# R7FA8D1BH register map
Vendor: Renesas; Series: RA8; File version: 1.2
CPU: CM85 r0p0, little endian, MPU, FPU, VTOR, 4 interrupt priority bits
Registers are 32-bit, read-write, reset 0x0 unless marked. A register's access mark holds for its fields unless they carry their own. Offsets are from the block's base; [hi:lo] are bit positions; 'fields as' and 'values as' point back to an identical list.

## MSTP — Module Stop Control A,B,C,D,E
Base 0x40203000
Same registers: MSTP_NS 0x50203000
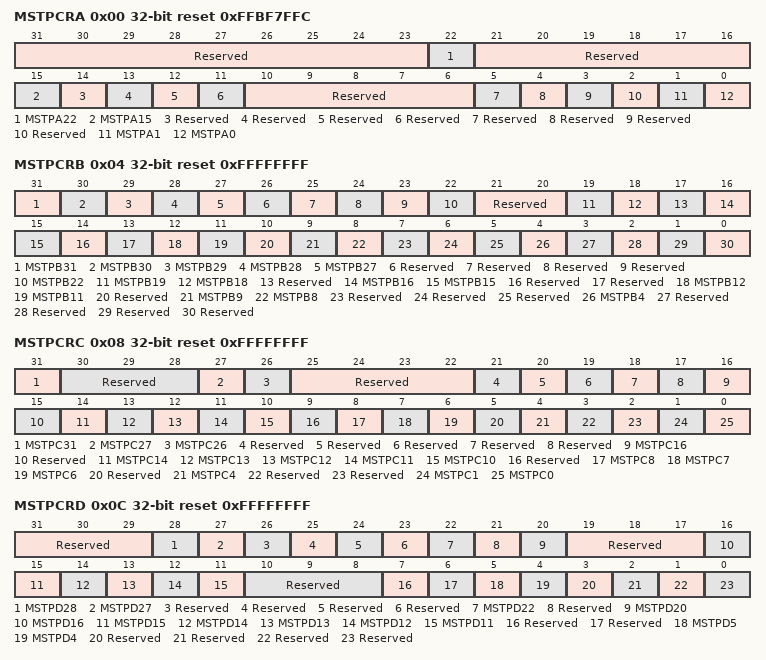
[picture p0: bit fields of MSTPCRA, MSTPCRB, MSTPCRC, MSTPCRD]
0x00 MSTPCRA reset 0xFFBF7FFC — Module Stop Control Register A
  [31:23] Reserved — These bits are read as 111111111. The write value should be 111111111.
  [22] MSTPA22 — DMA Controller/Data Transfer Controller unit0 Module Stop
    0=Cancel the module-stop state; 1=Enter the module-stop state
  [21:16] Reserved — These bits are read as 111111. The write value should be 111111.
  [15] MSTPA15 — Standby SRAM Module Module Stop
    values as MSTPA22
  [14] Reserved — This bit is read as 1. The write value should be 1.
  [13] Reserved — This bit is read as 1. The write value should be 1.
  [12] Reserved — This bit is read as 1. The write value should be 1.
  [11] Reserved — This bit is read as 1. The write value should be 1.
  [10:6] Reserved — These bits are read as 11111. The write value should be 11111.
  [5] Reserved — This bit is read as 1. The write value should be 1.
  [4] Reserved — This bit is read as 1. The write value should be 1.
  [3] Reserved — This bit is read as 1. The write value should be 1.
  [2] Reserved — This bit is read as 1. The write value should be 1.
  [1] MSTPA1 — SRAM1 Module Stop
    values as MSTPA22
  [0] MSTPA0 — SRAM0 Module Stop
    values as MSTPA22
0x04 MSTPCRB reset 0xFFFFFFFF — Module Stop Control Register B
  [31] MSTPB31 — Serial Communication Interface 0 Module Stop
    values as MSTPCRA.MSTPA22
  [30] MSTPB30 — Serial Communication Interface 1 Module Stop
    values as MSTPCRA.MSTPA22
  [29] MSTPB29 — Serial Communication Interface 2 Module Stop
    values as MSTPCRA.MSTPA22
  [28] MSTPB28 — Serial Communication Interface 3 Module Stop
    values as MSTPCRA.MSTPA22
  [27] MSTPB27 — Serial Communication Interface 4 Module Stop
    values as MSTPCRA.MSTPA22
  [26] Reserved — This bit is read as 1. The write value should be 1.
  [25] Reserved — This bit is read as 1. The write value should be 1.
  [24] Reserved — This bit is read as 1. The write value should be 1.
  [23] Reserved — This bit is read as 1. The write value should be 1.
  [22] MSTPB22 — Serial Communication Interface 9 Module Stop
    values as MSTPCRA.MSTPA22
  [21:20] Reserved — These bits are read as 11. The write value should be 11.
  [19] MSTPB19 — Serial Peripheral Interface 0 Module Stop
    values as MSTPCRA.MSTPA22
  [18] MSTPB18 — Serial Peripheral Interface 1 Module Stop
    values as MSTPCRA.MSTPA22
  [17] Reserved — This bit is read as 1. The write value should be 1.
  [16] MSTPB16 — Octa Memory Controller Module Stop
    values as MSTPCRA.MSTPA22
  [15] MSTPB15 — ETHERC0 and EDMAC0 Module Stop
    values as MSTPCRA.MSTPA22
  [14] Reserved — This bit is read as 1. The write value should be 1.
  [13] Reserved — This bit is read as 1. The write value should be 1.
  [12] MSTPB12 — Universal Serial Bus 2.0 HS Interface Module Stop
    values as MSTPCRA.MSTPA22
  [11] MSTPB11 — Universal Serial Bus 2.0 FS0 Interface Module Stop
    values as MSTPCRA.MSTPA22
  [10] Reserved — This bit is read as 1. The write value should be 1.
  [9] MSTPB9 — I2C Bus Interface 0 Module Stop
    values as MSTPCRA.MSTPA22
  [8] MSTPB8 — I2C Bus Interface 1 Module Stop
    values as MSTPCRA.MSTPA22
  [7] Reserved — This bit is read as 1. The write value should be 1.
  [6] Reserved — This bit is read as 1. The write value should be 1.
  [5] Reserved — This bit is read as 1. The write value should be 1.
  [4] MSTPB4 — I3C Bus Interface Module Stop
    values as MSTPCRA.MSTPA22
  [3] Reserved — This bit is read as 1. The write value should be 1.
  [2] Reserved — This bit is read as 1. The write value should be 1.
  [1] Reserved — This bit is read as 1. The write value should be 1.
  [0] Reserved — This bit is read as 1. The write value should be 1.
0x08 MSTPCRC reset 0xFFFFFFFF — Module Stop Control Register C
  [31] MSTPC31 — SHIP Module Stop
    values as MSTPCRA.MSTPA22
  [30:28] Reserved — These bits are read as 111. The write value should be 111.
  [27] MSTPC27 — Controller Area Network with Flexible Data-Rate 0 Module Stop
    values as MSTPCRA.MSTPA22
  [26] MSTPC26 — Controller Area Network with Flexible Data-Rate 1 Module Stop
    values as MSTPCRA.MSTPA22
  [25:22] Reserved — These bits are read as 1111. The write value should be 1111.
  [21] Reserved — This bit is read as 1. The write value should be 1.
  [20] Reserved — This bit is read as 1. The write value should be 1.
  [19] Reserved — This bit is read as 1. The write value should be 1.
  [18] Reserved — This bit is read as 1. The write value should be 1.
  [17] Reserved — This bit is read as 1. The write value should be 1.
  [16] MSTPC16 — CEU Module Stop
    values as MSTPCRA.MSTPA22
  [15] Reserved — This bit is read as 1. The write value should be 1.
  [14] MSTPC14 — Event Link Controller Module Stop
    values as MSTPCRA.MSTPA22
  [13] MSTPC13 — Data Operation Circuit Module Stop
    values as MSTPCRA.MSTPA22
  [12] MSTPC12 — Secure Digital Host IF 0 Module Stop
    values as MSTPCRA.MSTPA22
  [11] MSTPC11 — Secure Digital Host IF 1 Module Stop
    values as MSTPCRA.MSTPA22
  [10] MSTPC10 — MIPI Display Serial Interface Module Stop
    values as MSTPCRA.MSTPA22
  [9] Reserved — This bit is read as 1. The write value should be 1.
  [8] MSTPC8 — Serial Sound Interface0 Enhanced Module Stop
    values as MSTPCRA.MSTPA22
  [7] MSTPC7 — Serial Sound Interface1 Enhanced Module Stop
    values as MSTPCRA.MSTPA22
  [6] MSTPC6 — 2D Drawing Engine Module Stop
    values as MSTPCRA.MSTPA22
  [5] Reserved — This bit is read as 1. The write value should be 1.
  [4] MSTPC4 — Graphics LCD Controller Module Stop
    values as MSTPCRA.MSTPA22
  [3] Reserved — This bit is read as 1. The write value should be 1.
  [2] Reserved — This bit is read as 1. The write value should be 1.
  [1] MSTPC1 — Cyclic Redundancy Check Calculator Module Stop
    values as MSTPCRA.MSTPA22
  [0] MSTPC0 — Clock Frequency Accuracy Measurement Circuit Module Stop
    values as MSTPCRA.MSTPA22
0x0C MSTPCRD reset 0xFFFFFFFF — Module Stop Control Register D
  [31:29] Reserved — These bits are read as 111. The write value should be 111.
  [28] MSTPD28 — High-Speed Analog Com-parator 0 Module Stop
    values as MSTPCRA.MSTPA22
  [27] MSTPD27 — High-Speed Analog Com-parator 1 Module Stop
    values as MSTPCRA.MSTPA22
  [26] Reserved — This bit is read as 1. The write value should be 1.
  [25] Reserved — This bit is read as 1. The write value should be 1.
  [24] Reserved — This bit is read as 1. The write value should be 1.
  [23] Reserved — This bit is read as 1. The write value should be 1.
  [22] MSTPD22 — Temperature Sensor Module Stop
    values as MSTPCRA.MSTPA22
  [21] Reserved — This bit is read as 1. The write value should be 1.
  [20] MSTPD20 — 12-Bit D/A Converter Module Stop
    values as MSTPCRA.MSTPA22
  [19:17] Reserved — These bits are read as 111. The write value should be 111.
  [16] MSTPD16 — 12-bit A/D Converter 0 Module Stop
    values as MSTPCRA.MSTPA22
  [15] MSTPD15 — 12-bit A/D Converter 1 Module Stop
    values as MSTPCRA.MSTPA22
  [14] MSTPD14 — Port Output Enable for GPT0 Module Stop
    values as MSTPCRA.MSTPA22
  [13] MSTPD13 — Port Output Enable for GPT1 Module Stop
    values as MSTPCRA.MSTPA22
  [12] MSTPD12 — Port Output Enable for GPT2 Module Stop
    values as MSTPCRA.MSTPA22
  [11] MSTPD11 — Port Output Enable for GPT3 Module Stop
    values as MSTPCRA.MSTPA22
  [10:8] Reserved — These bits are read as 111. The write value should be 111.
  [7] Reserved — This bit is read as 1. The write value should be 1.
  [6] Reserved — This bit is read as 1. The write value should be 1.
  [5] MSTPD5 — Asynchronous General Purpose Timer 0 Module Stop
    values as MSTPCRA.MSTPA22
  [4] MSTPD4 — Asynchronous General Purpose Timer 1 Module Stop
    values as MSTPCRA.MSTPA22
  [3] Reserved — This bit is read as 1. The write value should be 1.
  [2] Reserved — This bit is read as 1. The write value should be 1.
  [1] Reserved — This bit is read as 1. The write value should be 1.
  [0] Reserved — This bit is read as 1. The write value should be 1.
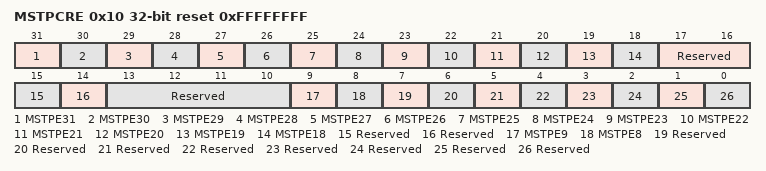
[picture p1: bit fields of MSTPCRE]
0x10 MSTPCRE reset 0xFFFFFFFF — Module Stop Control Register E
  [31] MSTPE31 — General PWM Timer 0 Module Stop
    values as MSTPCRA.MSTPA22
  [30] MSTPE30 — General PWM Timer 1 Module Stop
    values as MSTPCRA.MSTPA22
  [29] MSTPE29 — General PWM Timer 2 Module Stop
    values as MSTPCRA.MSTPA22
  [28] MSTPE28 — General PWM Timer 3 Module Stop
    values as MSTPCRA.MSTPA22
  [27] MSTPE27 — General PWM Timer 4 Module Stop
    values as MSTPCRA.MSTPA22
  [26] MSTPE26 — General PWM Timer 5 Module Stop
    values as MSTPCRA.MSTPA22
  [25] MSTPE25 — General PWM Timer 6 Module Stop
    values as MSTPCRA.MSTPA22
  [24] MSTPE24 — General PWM Timer 7 Module Stop
    values as MSTPCRA.MSTPA22
  [23] MSTPE23 — General PWM Timer 8 Module Stop
    values as MSTPCRA.MSTPA22
  [22] MSTPE22 — General PWM Timer 9 Module Stop
    values as MSTPCRA.MSTPA22
  [21] MSTPE21 — General PWM Timer 10 Module Stop
    values as MSTPCRA.MSTPA22
  [20] MSTPE20 — General PWM Timer 11 Module Stop
    values as MSTPCRA.MSTPA22
  [19] MSTPE19 — General PWM Timer 12 Module Stop
    values as MSTPCRA.MSTPA22
  [18] MSTPE18 — General PWM Timer 13 Module Stop
    values as MSTPCRA.MSTPA22
  [17:16] Reserved — These bits are read as 11. The write value should be 11.
  [15] Reserved — This bit is read as 1. The write value should be 1.
  [14] Reserved — This bit is read as 1. The write value should be 1.
  [13:10] Reserved — These bits are read as 1111. The write value should be 1111.
  [9] MSTPE9 — Ultra-Low Power Timer 0 Module Stop
    values as MSTPCRA.MSTPA22
  [8] MSTPE8 — Ultra-Low Power Timer 1 Module Stop
    values as MSTPCRA.MSTPA22
  [7] Reserved — This bit is read as 1. The write value should be 1.
  [6] Reserved — This bit is read as 1. The write value should be 1.
  [5] Reserved — This bit is read as 1. The write value should be 1.
  [4] Reserved — This bit is read as 1. The write value should be 1.
  [3] Reserved — This bit is read as 1. The write value should be 1.
  [2] Reserved — This bit is read as 1. The write value should be 1.
  [1] Reserved — This bit is read as 1. The write value should be 1.
  [0] Reserved — This bit is read as 1. The write value should be 1.
